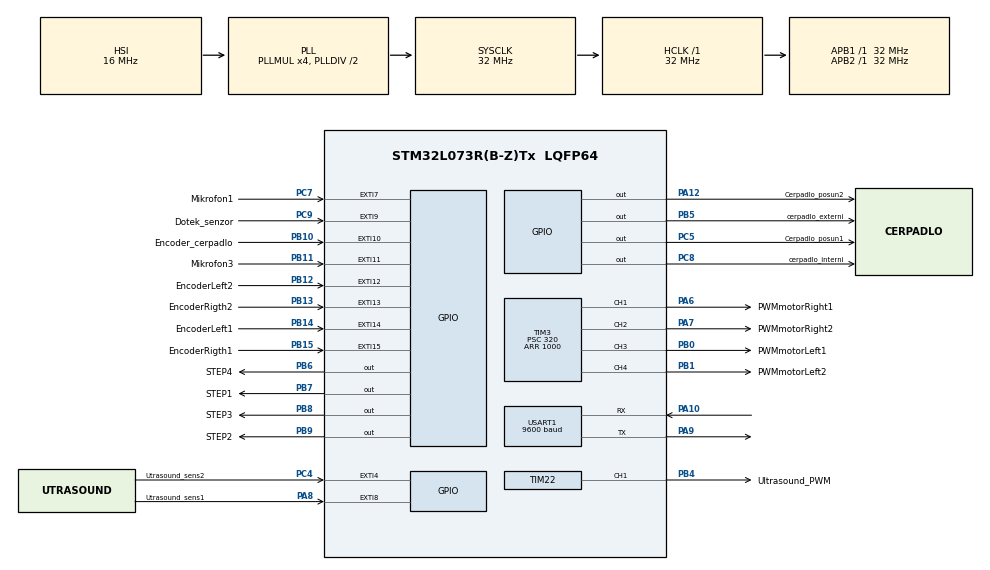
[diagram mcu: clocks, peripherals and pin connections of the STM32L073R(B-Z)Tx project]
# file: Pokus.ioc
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Dma.Request0=USART1_TX
Dma.Request1=USART1_RX
Dma.USART1_RX.1.Direction=DMA_PERIPH_TO_MEMORY
Dma.USART1_RX.1.Instance=DMA1_Channel3
Dma.USART1_RX.1.MemDataAlignment=DMA_MDATAALIGN_BYTE
Dma.USART1_RX.1.MemInc=DMA_MINC_ENABLE
Dma.USART1_RX.1.Mode=DMA_NORMAL
Dma.USART1_RX.1.PeriphDataAlignment=DMA_PDATAALIGN_BYTE
Dma.USART1_RX.1.PeriphInc=DMA_PINC_DISABLE
Dma.USART1_RX.1.Priority=DMA_PRIORITY_LOW
Dma.USART1_TX.0.Direction=DMA_MEMORY_TO_PERIPH
Dma.USART1_TX.0.Instance=DMA1_Channel2
Dma.USART1_TX.0.MemDataAlignment=DMA_MDATAALIGN_BYTE
Dma.USART1_TX.0.MemInc=DMA_MINC_ENABLE
Dma.USART1_TX.0.Mode=DMA_NORMAL
Dma.USART1_TX.0.PeriphDataAlignment=DMA_PDATAALIGN_BYTE
Dma.USART1_TX.0.PeriphInc=DMA_PINC_DISABLE
Dma.USART1_TX.0.Priority=DMA_PRIORITY_LOW
Mcu.Family=STM32L0
Mcu.Name=STM32L073R(B-Z)Tx
Mcu.Package=LQFP64
NVIC.DMA1_Channel2_3_IRQn=true\:0\:0\:false\:false\:true\:false
NVIC.EXTI4_15_IRQn=true\:0\:0\:false\:false\:true\:true
NVIC.TIM22_IRQn=true\:0\:0\:false\:false\:true\:true
NVIC.TIM3_IRQn=true\:0\:0\:false\:false\:true\:true
NVIC.TIM6_DAC_IRQn=true\:0\:0\:false\:false\:true\:true
NVIC.USART1_IRQn=true\:0\:0\:false\:false\:true\:true
PA10.Mode=Asynchronous
PA10.Signal=USART1_RX
PA12.GPIO_Label=Cerpadlo_posun2
PA12.GPIO_Speed=GPIO_SPEED_FREQ_MEDIUM
PA12.Signal=GPIO_Output
PA6.GPIO_Label=PWMmotorRight1
PA6.Signal=S_TIM3_CH1
PA7.GPIO_Label=PWMmotorRight2
PA7.Signal=S_TIM3_CH2
PA8.GPIO_Label=Utrasound_sens1
PA8.GPIO_ModeDefaultEXTI=GPIO_MODE_IT_RISING_FALLING
PA8.GPIO_PuPd=GPIO_NOPULL
PA8.Signal=GPXTI8
PA9.Mode=Asynchronous
PA9.Signal=USART1_TX
PB0.GPIO_Label=PWMmotorLeft1
PB0.Signal=S_TIM3_CH3
PB1.GPIO_Label=PWMmotorLeft2
PB1.Signal=S_TIM3_CH4
PB10.GPIO_Label=Encoder_cerpadlo
PB10.Signal=GPXTI10
PB11.GPIO_Label=Mikrofon3
PB11.Signal=GPXTI11
PB12.GPIO_Label=EncoderLeft2
PB12.Signal=GPXTI12
PB13.GPIO_Label=EncoderRigth2
PB13.Signal=GPXTI13
PB14.GPIO_Label=EncoderLeft1
PB14.Signal=GPXTI14
PB15.GPIO_Label=EncoderRigth1
PB15.Signal=GPXTI15
PB4.GPIO_Label=Ultrasound_PWM
PB4.GPIO_PuPd=GPIO_PULLDOWN
PB4.GPIO_Speed=GPIO_SPEED_FREQ_MEDIUM
PB4.Signal=S_TIM22_CH1
PB5.GPIO_Label=cerpadlo_externi
PB5.Signal=GPIO_Output
PB6.GPIO_Label=STEP4
PB6.Signal=GPIO_Output
PB7.GPIO_Label=STEP1
PB7.Signal=GPIO_Output
PB8.GPIO_Label=STEP3
PB8.Signal=GPIO_Output
PB9.GPIO_Label=STEP2
PB9.Signal=GPIO_Output
PC14-OSC32_IN.Mode=LSE-External-Oscillator
PC14-OSC32_IN.Signal=RCC_OSC32_IN
PC15-OSC32_OUT.Mode=LSE-External-Oscillator
PC15-OSC32_OUT.Signal=RCC_OSC32_OUT
PC4.GPIO_Label=Utrasound_sens2
PC4.GPIO_ModeDefaultEXTI=GPIO_MODE_IT_RISING_FALLING
PC4.Signal=GPXTI4
PC5.GPIO_Label=Cerpadlo_posun1
PC5.GPIO_Speed=GPIO_SPEED_FREQ_MEDIUM
PC5.Signal=GPIO_Output
PC7.GPIO_Label=Mikrofon1
PC7.Signal=GPXTI7
PC8.GPIO_Label=cerpadlo_interni
PC8.Signal=GPIO_Output
PC9.GPIO_Label=Dotek_senzor
PC9.GPIO_PuPd=GPIO_PULLDOWN
PC9.Signal=GPXTI9
ProjectManager.HeapSize=0x200
ProjectManager.StackSize=0x400
ProjectManager.TargetToolchain=SW4STM32
RCC.AHBFreq_Value=32000000
RCC.APB1Freq_Value=32000000
RCC.APB1TimFreq_Value=32000000
RCC.APB2Freq_Value=32000000
RCC.APB2TimFreq_Value=32000000
RCC.HCLKFreq_Value=32000000
RCC.HSE_VALUE=8000000
RCC.HSI16_VALUE=16000000
RCC.HSI48_VALUE=48000000
RCC.HSI_VALUE=16000000
RCC.MSI_VALUE=2097000
RCC.PLLMUL=RCC_PLLMUL_4
RCC.SYSCLKFreq_VALUE=32000000
RCC.SYSCLKSource=RCC_SYSCLKSOURCE_PLLCLK
RCC.VCOOutputFreq_Value=64000000
SH.S_TIM22_CH1.0=TIM22_CH1,PWM Generation1 CH1
SH.S_TIM3_CH1.0=TIM3_CH1,PWM Generation1 CH1
SH.S_TIM3_CH2.0=TIM3_CH2,PWM Generation2 CH2
SH.S_TIM3_CH3.0=TIM3_CH3,PWM Generation3 CH3
SH.S_TIM3_CH4.0=TIM3_CH4,PWM Generation4 CH4
TIM22.Channel-PWM\ Generation1\ CH1=TIM_CHANNEL_1
TIM22.Period=65000
TIM22.Prescaler=32
TIM22.Pulse-PWM\ Generation1\ CH1=10
TIM3.Channel-PWM\ Generation1\ CH1=TIM_CHANNEL_1
TIM3.Channel-PWM\ Generation2\ CH2=TIM_CHANNEL_2
TIM3.Channel-PWM\ Generation3\ CH3=TIM_CHANNEL_3
TIM3.Channel-PWM\ Generation4\ CH4=TIM_CHANNEL_4
TIM3.Period=1000
TIM3.Prescaler=320
TIM6.Period=65000
TIM6.Prescaler=320
USART1.BaudRate=9600
USART1.VirtualMode-Asynchronous=VM_ASYNC
VP_TIM22_VS_ClockSourceINT.Mode=Internal
VP_TIM3_VS_ClockSourceINT.Mode=Internal
VP_TIM6_VS_ClockSourceINT.Mode=Enable_Timer
board=custom

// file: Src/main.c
/* USER CODE BEGIN Header */
/**
  ******************************************************************************
  * @file           : main.c
  * @brief          : Main program body
  ******************************************************************************
  ** This notice applies to any and all portions of this file
  * that are not between comment pairs USER CODE BEGIN and
  * USER CODE END. Other portions of this file, whether
  * inserted by the user or by software development tools
  * are owned by their respective copyright owners.
  *
  * COPYRIGHT(c) 2019 STMicroelectronics
  *
  * Redistribution and use in source and binary forms, with or without modification,
  * are permitted provided that the following conditions are met:
  *   1. Redistributions of source code must retain the above copyright notice,
  *      this list of conditions and the following disclaimer.
  *   2. Redistributions in binary form must reproduce the above copyright notice,
  *      this list of conditions and the following disclaimer in the documentation
  *      and/or other materials provided with the distribution.
  *   3. Neither the name of STMicroelectronics nor the names of its contributors
  *      may be used to endorse or promote products derived from this software
  *      without specific prior written permission.
  *
  * THIS SOFTWARE IS PROVIDED BY THE COPYRIGHT HOLDERS AND CONTRIBUTORS "AS IS"
  * AND ANY EXPRESS OR IMPLIED WARRANTIES, INCLUDING, BUT NOT LIMITED TO, THE
  * IMPLIED WARRANTIES OF MERCHANTABILITY AND FITNESS FOR A PARTICULAR PURPOSE ARE
  * DISCLAIMED. IN NO EVENT SHALL THE COPYRIGHT HOLDER OR CONTRIBUTORS BE LIABLE
  * FOR ANY DIRECT, INDIRECT, INCIDENTAL, SPECIAL, EXEMPLARY, OR CONSEQUENTIAL
  * DAMAGES (INCLUDING, BUT NOT LIMITED TO, PROCUREMENT OF SUBSTITUTE GOODS OR
  * SERVICES; LOSS OF USE, DATA, OR PROFITS; OR BUSINESS INTERRUPTION) HOWEVER
  * CAUSED AND ON ANY THEORY OF LIABILITY, WHETHER IN CONTRACT, STRICT LIABILITY,
  * OR TORT (INCLUDING NEGLIGENCE OR OTHERWISE) ARISING IN ANY WAY OUT OF THE USE
  * OF THIS SOFTWARE, EVEN IF ADVISED OF THE POSSIBILITY OF SUCH DAMAGE.
  *
  ******************************************************************************
  */
/* USER CODE END Header */

#include "main.h"

/* USER CODE BEGIN Includes */
#include "motorcontrol.h"
#include "Bluetooth.h"
#include "Ultrasound.h"
#include "Step_eng.h"
#include "Cerpadlo.h"
//#include "navigator.h"
/* USER CODE END Includes */

TIM_HandleTypeDef htim3;
TIM_HandleTypeDef htim6;
TIM_HandleTypeDef htim22;

UART_HandleTypeDef huart1;
DMA_HandleTypeDef hdma_usart1_tx;
DMA_HandleTypeDef hdma_usart1_rx;

void SystemClock_Config(void);
static void MX_GPIO_Init(void);
static void MX_DMA_Init(void);
static void MX_TIM3_Init(void);
static void MX_USART1_UART_Init(void);
static void MX_TIM6_Init(void);
static void MX_TIM22_Init(void);

int main(void)
{

  /* MCU Configuration--------------------------------------------------------*/

  /* Reset of all peripherals, Initializes the Flash interface and the Systick. */
  HAL_Init();

  /* Configure the system clock */
  SystemClock_Config();

  /* Initialize all configured peripherals */
  MX_GPIO_Init();
  MX_DMA_Init();
  MX_TIM3_Init();
  MX_USART1_UART_Init();
  MX_TIM6_Init();
  MX_TIM22_Init();
  /* USER CODE BEGIN 2 */
  init_ultrasound(&htim22);
  start_motor_control(&htim3);
  //start_cerpadlo_control();
  init_PID();
  init_PID_ultrazvuk();
  start_encoder();
  start_bluetooth(&huart1);

  //Motor_left(&htim3,10,200);
  //Motor_right(&htim3,10,200);
  //Motor_straigt(&htim3,100,400);
  //Travel_rovne(&htim3,100,400);
  set_speed(&htim3,600,600);
  while(1)
  {
	  PID_podle_ultrazvuku(&htim3);
  }
  Parkovani(&htim3,400);

  /*

   int rigth = 200; //speed of rigth engine
  	int left = 200; //speed of left engine
  	set_speed(&htim3,left,rigth);

  while (1)
  {
	// PID_regularor(&htim3); //call PID regulator with its own frequency 100Hz

	  if (dist1<1700)
	  	 			  {
	  	 				  rigth = 0; //speed of rigth engine
	  	 				  left = 0; //speed of left engine
	  	 				 set_speed(&htim3,left,rigth);
	  	 			  }
	  	 if (dist1>3000)
	  	 			  {
	  	 				   rigth = 200; //speed of rigth engine
	  	 				   left = 200; //speed of left engine
	  	 				set_speed(&htim3,left,rigth);
	  	 			  }

		 }

*/

/*
  posun_cerpadla(nahoru);
  Travel_rovne(&htim3,10,600);
  HAL_Delay(1000);
  posun_cerpadla(dolu);
  HAL_Delay(1000);
  start_cerpani_v_rameni(800); //10 = 1s
  posun_cerpadla(nahoru);
  set_stop(0,0);
  Travel_rovne(&htim3,0.5,-500);
  HAL_Delay(1000);
  set_stop(0,0);
  Travel_turn(&htim3,80,1000);
  HAL_Delay(1000);
  set_stop(0,0);
  Travel_rovne(&htim3,10,600);
  HAL_Delay(1000);
  start_cerpani_v_nadrzi(800); //10 = 1s
*/

  /* USER CODE END 2 */

  /* Infinite loop */
  /* USER CODE BEGIN WHILE */
  while (1)
  {
	  /*
	  set_stop(0,0);
	  Travel_rovne(&htim3,100,500);
	  set_stop(0,0);
	  HAL_Delay(1000);
	  Travel_rovne(&htim3,100,100);
	  posun_cerpadla(dolu);
	  posun_cerpadla(nahoru
	  );
	  HAL_Delay(1000);
	  start_cerpani_v_nadrzi(1000);
	  start_cerpani_v_rameni(1000);
	  */

    /* USER CODE END WHILE */

  }
}

void SystemClock_Config(void)
{
  RCC_OscInitTypeDef RCC_OscInitStruct = {0};
  RCC_ClkInitTypeDef RCC_ClkInitStruct = {0};
  RCC_PeriphCLKInitTypeDef PeriphClkInit = {0};

  /**Configure the main internal regulator output voltage
  */
  __HAL_PWR_VOLTAGESCALING_CONFIG(PWR_REGULATOR_VOLTAGE_SCALE1);
  /**Initializes the CPU, AHB and APB busses clocks
  */
  RCC_OscInitStruct.OscillatorType = RCC_OSCILLATORTYPE_HSI;
  RCC_OscInitStruct.HSIState = RCC_HSI_ON;
  RCC_OscInitStruct.HSICalibrationValue = RCC_HSICALIBRATION_DEFAULT;
  RCC_OscInitStruct.PLL.PLLState = RCC_PLL_ON;
  RCC_OscInitStruct.PLL.PLLSource = RCC_PLLSOURCE_HSI;
  RCC_OscInitStruct.PLL.PLLMUL = RCC_PLLMUL_4;
  RCC_OscInitStruct.PLL.PLLDIV = RCC_PLLDIV_2;
  if (HAL_RCC_OscConfig(&RCC_OscInitStruct) != HAL_OK)
  {
    Error_Handler();
  }
  /**Initializes the CPU, AHB and APB busses clocks
  */
  RCC_ClkInitStruct.ClockType = RCC_CLOCKTYPE_HCLK|RCC_CLOCKTYPE_SYSCLK
                              |RCC_CLOCKTYPE_PCLK1|RCC_CLOCKTYPE_PCLK2;
  RCC_ClkInitStruct.SYSCLKSource = RCC_SYSCLKSOURCE_PLLCLK;
  RCC_ClkInitStruct.AHBCLKDivider = RCC_SYSCLK_DIV1;
  RCC_ClkInitStruct.APB1CLKDivider = RCC_HCLK_DIV1;
  RCC_ClkInitStruct.APB2CLKDivider = RCC_HCLK_DIV1;

  if (HAL_RCC_ClockConfig(&RCC_ClkInitStruct, FLASH_LATENCY_1) != HAL_OK)
  {
    Error_Handler();
  }
  PeriphClkInit.PeriphClockSelection = RCC_PERIPHCLK_USART1;
  PeriphClkInit.Usart1ClockSelection = RCC_USART1CLKSOURCE_PCLK2;
  if (HAL_RCCEx_PeriphCLKConfig(&PeriphClkInit) != HAL_OK)
  {
    Error_Handler();
  }
}

static void MX_TIM3_Init(void)
{

  TIM_ClockConfigTypeDef sClockSourceConfig = {0};
  TIM_MasterConfigTypeDef sMasterConfig = {0};
  TIM_OC_InitTypeDef sConfigOC = {0};

  htim3.Instance = TIM3;
  htim3.Init.Prescaler = 320;
  htim3.Init.CounterMode = TIM_COUNTERMODE_UP;
  htim3.Init.Period = 1000;
  htim3.Init.ClockDivision = TIM_CLOCKDIVISION_DIV1;
  htim3.Init.AutoReloadPreload = TIM_AUTORELOAD_PRELOAD_DISABLE;
  if (HAL_TIM_Base_Init(&htim3) != HAL_OK)
  {
    Error_Handler();
  }
  sClockSourceConfig.ClockSource = TIM_CLOCKSOURCE_INTERNAL;
  if (HAL_TIM_ConfigClockSource(&htim3, &sClockSourceConfig) != HAL_OK)
  {
    Error_Handler();
  }
  if (HAL_TIM_PWM_Init(&htim3) != HAL_OK)
  {
    Error_Handler();
  }
  sMasterConfig.MasterOutputTrigger = TIM_TRGO_RESET;
  sMasterConfig.MasterSlaveMode = TIM_MASTERSLAVEMODE_DISABLE;
  if (HAL_TIMEx_MasterConfigSynchronization(&htim3, &sMasterConfig) != HAL_OK)
  {
    Error_Handler();
  }
  sConfigOC.OCMode = TIM_OCMODE_PWM1;
  sConfigOC.Pulse = 0;
  sConfigOC.OCPolarity = TIM_OCPOLARITY_HIGH;
  sConfigOC.OCFastMode = TIM_OCFAST_DISABLE;
  if (HAL_TIM_PWM_ConfigChannel(&htim3, &sConfigOC, TIM_CHANNEL_1) != HAL_OK)
  {
    Error_Handler();
  }
  if (HAL_TIMEx_RemapConfig(&htim3, TIM3_TI1_GPIO) != HAL_OK)
  {
    Error_Handler();
  }
  if (HAL_TIM_PWM_ConfigChannel(&htim3, &sConfigOC, TIM_CHANNEL_2) != HAL_OK)
  {
    Error_Handler();
  }
  if (HAL_TIM_PWM_ConfigChannel(&htim3, &sConfigOC, TIM_CHANNEL_3) != HAL_OK)
  {
    Error_Handler();
  }
  if (HAL_TIM_PWM_ConfigChannel(&htim3, &sConfigOC, TIM_CHANNEL_4) != HAL_OK)
  {
    Error_Handler();
  }
  HAL_TIM_MspPostInit(&htim3);

}

static void MX_TIM6_Init(void)
{

  TIM_MasterConfigTypeDef sMasterConfig = {0};

  htim6.Instance = TIM6;
  htim6.Init.Prescaler = 320;
  htim6.Init.CounterMode = TIM_COUNTERMODE_UP;
  htim6.Init.Period = 65000;
  htim6.Init.AutoReloadPreload = TIM_AUTORELOAD_PRELOAD_DISABLE;
  if (HAL_TIM_Base_Init(&htim6) != HAL_OK)
  {
    Error_Handler();
  }
  sMasterConfig.MasterOutputTrigger = TIM_TRGO_RESET;
  sMasterConfig.MasterSlaveMode = TIM_MASTERSLAVEMODE_DISABLE;
  if (HAL_TIMEx_MasterConfigSynchronization(&htim6, &sMasterConfig) != HAL_OK)
  {
    Error_Handler();
  }

}

static void MX_TIM22_Init(void)
{

  TIM_ClockConfigTypeDef sClockSourceConfig = {0};
  TIM_MasterConfigTypeDef sMasterConfig = {0};
  TIM_OC_InitTypeDef sConfigOC = {0};

  htim22.Instance = TIM22;
  htim22.Init.Prescaler = 32;
  htim22.Init.CounterMode = TIM_COUNTERMODE_UP;
  htim22.Init.Period = 65000;
  htim22.Init.ClockDivision = TIM_CLOCKDIVISION_DIV1;
  htim22.Init.AutoReloadPreload = TIM_AUTORELOAD_PRELOAD_DISABLE;
  if (HAL_TIM_Base_Init(&htim22) != HAL_OK)
  {
    Error_Handler();
  }
  sClockSourceConfig.ClockSource = TIM_CLOCKSOURCE_INTERNAL;
  if (HAL_TIM_ConfigClockSource(&htim22, &sClockSourceConfig) != HAL_OK)
  {
    Error_Handler();
  }
  if (HAL_TIM_PWM_Init(&htim22) != HAL_OK)
  {
    Error_Handler();
  }
  sMasterConfig.MasterOutputTrigger = TIM_TRGO_RESET;
  sMasterConfig.MasterSlaveMode = TIM_MASTERSLAVEMODE_DISABLE;
  if (HAL_TIMEx_MasterConfigSynchronization(&htim22, &sMasterConfig) != HAL_OK)
  {
    Error_Handler();
  }
  sConfigOC.OCMode = TIM_OCMODE_PWM1;
  sConfigOC.Pulse = 10;
  sConfigOC.OCPolarity = TIM_OCPOLARITY_HIGH;
  sConfigOC.OCFastMode = TIM_OCFAST_DISABLE;
  if (HAL_TIM_PWM_ConfigChannel(&htim22, &sConfigOC, TIM_CHANNEL_1) != HAL_OK)
  {
    Error_Handler();
  }
  if (HAL_TIMEx_RemapConfig(&htim22, TIM3_TI1_GPIO) != HAL_OK)
  {
    Error_Handler();
  }
  HAL_TIM_MspPostInit(&htim22);

}

static void MX_USART1_UART_Init(void)
{

  huart1.Instance = USART1;
  huart1.Init.BaudRate = 9600;
  huart1.Init.WordLength = UART_WORDLENGTH_8B;
  huart1.Init.StopBits = UART_STOPBITS_1;
  huart1.Init.Parity = UART_PARITY_NONE;
  huart1.Init.Mode = UART_MODE_TX_RX;
  huart1.Init.HwFlowCtl = UART_HWCONTROL_NONE;
  huart1.Init.OverSampling = UART_OVERSAMPLING_16;
  huart1.Init.OneBitSampling = UART_ONE_BIT_SAMPLE_DISABLE;
  huart1.AdvancedInit.AdvFeatureInit = UART_ADVFEATURE_NO_INIT;
  if (HAL_UART_Init(&huart1) != HAL_OK)
  {
    Error_Handler();
  }

}

static void MX_DMA_Init(void)
{
  /* DMA controller clock enable */
  __HAL_RCC_DMA1_CLK_ENABLE();

  /* DMA interrupt init */
  /* DMA1_Channel2_3_IRQn interrupt configuration */
  HAL_NVIC_SetPriority(DMA1_Channel2_3_IRQn, 0, 0);
  HAL_NVIC_EnableIRQ(DMA1_Channel2_3_IRQn);

}

static void MX_GPIO_Init(void)
{
  GPIO_InitTypeDef GPIO_InitStruct = {0};

  /* GPIO Ports Clock Enable */
  __HAL_RCC_GPIOC_CLK_ENABLE();
  __HAL_RCC_GPIOA_CLK_ENABLE();
  __HAL_RCC_GPIOB_CLK_ENABLE();

  /*Configure GPIO pin Output Level */
  HAL_GPIO_WritePin(GPIOC, Cerpadlo_posun1_Pin|cerpadlo_interni_Pin, GPIO_PIN_RESET);

  /*Configure GPIO pin Output Level */
  HAL_GPIO_WritePin(Cerpadlo_posun2_GPIO_Port, Cerpadlo_posun2_Pin, GPIO_PIN_RESET);

  /*Configure GPIO pin Output Level */
  HAL_GPIO_WritePin(GPIOB, cerpadlo_externi_Pin|STEP4_Pin|STEP1_Pin|STEP3_Pin
                          |STEP2_Pin, GPIO_PIN_RESET);

  /*Configure GPIO pin : Utrasound_sens2_Pin */
  GPIO_InitStruct.Pin = Utrasound_sens2_Pin;
  GPIO_InitStruct.Mode = GPIO_MODE_IT_RISING_FALLING;
  GPIO_InitStruct.Pull = GPIO_NOPULL;
  HAL_GPIO_Init(Utrasound_sens2_GPIO_Port, &GPIO_InitStruct);

  /*Configure GPIO pin : Cerpadlo_posun1_Pin */
  GPIO_InitStruct.Pin = Cerpadlo_posun1_Pin;
  GPIO_InitStruct.Mode = GPIO_MODE_OUTPUT_PP;
  GPIO_InitStruct.Pull = GPIO_NOPULL;
  GPIO_InitStruct.Speed = GPIO_SPEED_FREQ_MEDIUM;
  HAL_GPIO_Init(Cerpadlo_posun1_GPIO_Port, &GPIO_InitStruct);

  /*Configure GPIO pins : Encoder_cerpadlo_Pin Mikrofon3_Pin EncoderLeft2_Pin EncoderRigth2_Pin
                           EncoderLeft1_Pin EncoderRigth1_Pin */
  GPIO_InitStruct.Pin = Encoder_cerpadlo_Pin|Mikrofon3_Pin|EncoderLeft2_Pin|EncoderRigth2_Pin
                          |EncoderLeft1_Pin|EncoderRigth1_Pin;
  GPIO_InitStruct.Mode = GPIO_MODE_IT_RISING;
  GPIO_InitStruct.Pull = GPIO_NOPULL;
  HAL_GPIO_Init(GPIOB, &GPIO_InitStruct);

  /*Configure GPIO pin : Mikrofon1_Pin */
  GPIO_InitStruct.Pin = Mikrofon1_Pin;
  GPIO_InitStruct.Mode = GPIO_MODE_IT_RISING;
  GPIO_InitStruct.Pull = GPIO_NOPULL;
  HAL_GPIO_Init(Mikrofon1_GPIO_Port, &GPIO_InitStruct);

  /*Configure GPIO pin : cerpadlo_interni_Pin */
  GPIO_InitStruct.Pin = cerpadlo_interni_Pin;
  GPIO_InitStruct.Mode = GPIO_MODE_OUTPUT_PP;
  GPIO_InitStruct.Pull = GPIO_NOPULL;
  GPIO_InitStruct.Speed = GPIO_SPEED_FREQ_LOW;
  HAL_GPIO_Init(cerpadlo_interni_GPIO_Port, &GPIO_InitStruct);

  /*Configure GPIO pin : Dotek_senzor_Pin */
  GPIO_InitStruct.Pin = Dotek_senzor_Pin;
  GPIO_InitStruct.Mode = GPIO_MODE_IT_RISING;
  GPIO_InitStruct.Pull = GPIO_PULLDOWN;
  HAL_GPIO_Init(Dotek_senzor_GPIO_Port, &GPIO_InitStruct);

  /*Configure GPIO pin : Utrasound_sens1_Pin */
  GPIO_InitStruct.Pin = Utrasound_sens1_Pin;
  GPIO_InitStruct.Mode = GPIO_MODE_IT_RISING_FALLING;
  GPIO_InitStruct.Pull = GPIO_NOPULL;
  HAL_GPIO_Init(Utrasound_sens1_GPIO_Port, &GPIO_InitStruct);

  /*Configure GPIO pin : Cerpadlo_posun2_Pin */
  GPIO_InitStruct.Pin = Cerpadlo_posun2_Pin;
  GPIO_InitStruct.Mode = GPIO_MODE_OUTPUT_PP;
  GPIO_InitStruct.Pull = GPIO_NOPULL;
  GPIO_InitStruct.Speed = GPIO_SPEED_FREQ_MEDIUM;
  HAL_GPIO_Init(Cerpadlo_posun2_GPIO_Port, &GPIO_InitStruct);

  /*Configure GPIO pins : cerpadlo_externi_Pin STEP4_Pin STEP1_Pin STEP3_Pin
                           STEP2_Pin */
  GPIO_InitStruct.Pin = cerpadlo_externi_Pin|STEP4_Pin|STEP1_Pin|STEP3_Pin
                          |STEP2_Pin;
  GPIO_InitStruct.Mode = GPIO_MODE_OUTPUT_PP;
  GPIO_InitStruct.Pull = GPIO_NOPULL;
  GPIO_InitStruct.Speed = GPIO_SPEED_FREQ_LOW;
  HAL_GPIO_Init(GPIOB, &GPIO_InitStruct);

  /* EXTI interrupt init*/
  HAL_NVIC_SetPriority(EXTI4_15_IRQn, 0, 0);
  HAL_NVIC_EnableIRQ(EXTI4_15_IRQn);

}

void Error_Handler(void)
{
}

/************************ (C) COPYRIGHT STMicroelectronics *****END OF FILE****/
